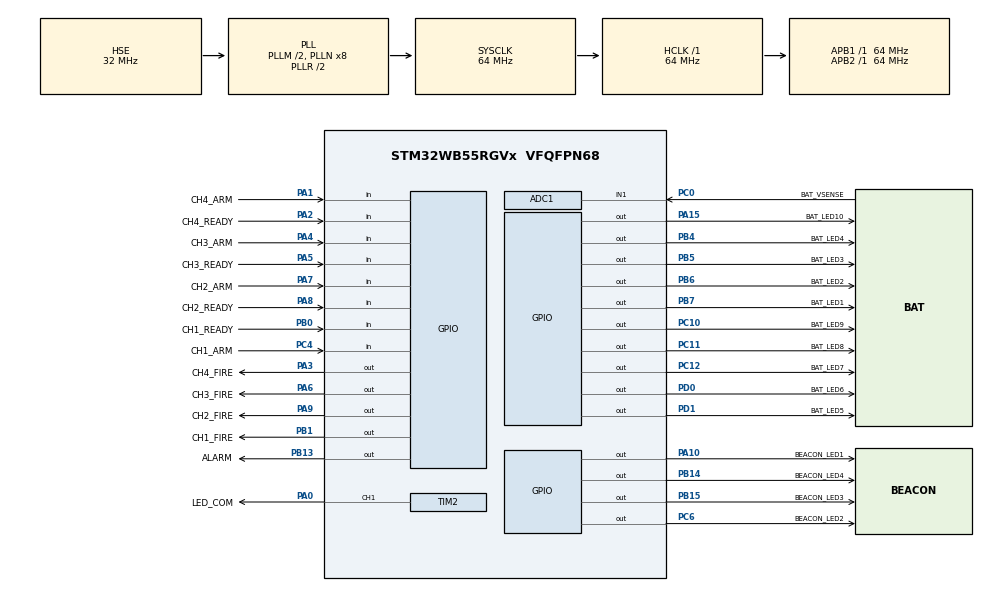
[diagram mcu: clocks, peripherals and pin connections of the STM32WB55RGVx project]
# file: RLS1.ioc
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ADC1.Channel-0\#ChannelRegularConversion=ADC_CHANNEL_1
ADC1.NbrOfConversionFlag=1
ADC1.OffsetNumber-0\#ChannelRegularConversion=ADC_OFFSET_NONE
ADC1.Rank-0\#ChannelRegularConversion=1
ADC1.SamplingTime-0\#ChannelRegularConversion=ADC_SAMPLETIME_12CYCLES_5
ADC1.master=1
Dma.Request0=TIM2_CH1
Dma.TIM2_CH1.0.Direction=DMA_MEMORY_TO_PERIPH
Dma.TIM2_CH1.0.EventEnable=DISABLE
Dma.TIM2_CH1.0.Instance=DMA1_Channel1
Dma.TIM2_CH1.0.MemDataAlignment=DMA_MDATAALIGN_BYTE
Dma.TIM2_CH1.0.MemInc=DMA_MINC_ENABLE
Dma.TIM2_CH1.0.Mode=DMA_NORMAL
Dma.TIM2_CH1.0.PeriphDataAlignment=DMA_PDATAALIGN_WORD
Dma.TIM2_CH1.0.PeriphInc=DMA_PINC_DISABLE
Dma.TIM2_CH1.0.Polarity=HAL_DMAMUX_REQ_GEN_RISING
Dma.TIM2_CH1.0.Priority=DMA_PRIORITY_LOW
Dma.TIM2_CH1.0.RequestNumber=1
Dma.TIM2_CH1.0.SignalID=NONE
Dma.TIM2_CH1.0.SyncEnable=DISABLE
Dma.TIM2_CH1.0.SyncPolarity=HAL_DMAMUX_SYNC_NO_EVENT
Dma.TIM2_CH1.0.SyncRequestNumber=1
Dma.TIM2_CH1.0.SyncSignalID=NONE
FREERTOS.Tasks01=defaultTask,24,128,StartDefaultTask,Default,NULL,Dynamic,NULL,NULL
FREERTOS.configTOTAL_HEAP_SIZE=20 * 1024
FREERTOS.configUSE_NEWLIB_REENTRANT=1
Mcu.Family=STM32WB
Mcu.Name=STM32WB55RGVx
Mcu.Package=VFQFPN68
NVIC.DMA1_Channel1_IRQn=true\:5\:0\:false\:false\:true\:true\:false\:true\:true
NVIC.HSEM_IRQn=true\:5\:0\:false\:false\:true\:true\:false\:true\:true
NVIC.IPCC_C1_RX_IRQn=true\:5\:0\:false\:false\:true\:true\:true\:true\:true
NVIC.IPCC_C1_TX_IRQn=true\:5\:0\:false\:false\:true\:true\:true\:true\:true
NVIC.PriorityGroup=NVIC_PRIORITYGROUP_4
NVIC.TIM1_TRG_COM_TIM17_IRQn=true\:15\:0\:false\:false\:true\:false\:false\:true\:true
NVIC.TIM2_IRQn=true\:5\:0\:false\:false\:true\:true\:true\:true\:true
NVIC.TimeBase=TIM1_TRG_COM_TIM17_IRQn
NVIC.TimeBaseIP=TIM17
OSC_IN.Mode=HSE-External-Oscillator
OSC_IN.Signal=RCC_OSC_IN
OSC_OUT.Mode=HSE-External-Oscillator
OSC_OUT.Signal=RCC_OSC_OUT
PA0.GPIO_Label=LED_COM
PA0.Signal=S_TIM2_CH1
PA1.GPIO_Label=CH4_ARM
PA1.Signal=GPIO_Input
PA10.GPIO_Label=BEACON_LED1
PA10.GPIO_ModeDefaultOutputPP=GPIO_MODE_OUTPUT_PP
PA10.GPIO_PuPd=GPIO_NOPULL
PA10.PinState=GPIO_PIN_RESET
PA10.Signal=GPIO_Output
PA13.Mode=Trace_Asynchronous_SW
PA13.Signal=SYS_JTMS-SWDIO
PA14.Mode=Trace_Asynchronous_SW
PA14.Signal=SYS_JTCK-SWCLK
PA15.GPIO_Label=BAT_LED10
PA15.GPIO_ModeDefaultOutputPP=GPIO_MODE_OUTPUT_OD
PA15.GPIO_PuPd=GPIO_NOPULL
PA15.PinState=GPIO_PIN_SET
PA15.Signal=GPIO_Output
PA2.GPIO_Label=CH4_READY
PA2.Signal=GPIO_Input
PA3.GPIO_Label=CH4_FIRE
PA3.Signal=GPIO_Output
PA4.GPIO_Label=CH3_ARM
PA4.Signal=GPIO_Input
PA5.GPIO_Label=CH3_READY
PA5.Signal=GPIO_Input
PA6.GPIO_Label=CH3_FIRE
PA6.Signal=GPIO_Output
PA7.GPIO_Label=CH2_ARM
PA7.Signal=GPIO_Input
PA8.GPIO_Label=CH2_READY
PA8.Signal=GPIO_Input
PA9.GPIO_Label=CH2_FIRE
PA9.Signal=GPIO_Output
PB0.GPIO_Label=CH1_READY
PB0.Signal=GPIO_Input
PB1.GPIO_Label=CH1_FIRE
PB1.Signal=GPIO_Output
PB13.GPIO_Label=ALARM
PB13.Signal=GPIO_Output
PB14.GPIO_Label=BEACON_LED4
PB14.Signal=GPIO_Output
PB15.GPIO_Label=BEACON_LED3
PB15.Signal=GPIO_Output
PB3.Mode=Trace_Asynchronous_SW
PB3.Signal=SYS_JTDO-SWO
PB4.GPIO_Label=BAT_LED4
PB4.GPIO_ModeDefaultOutputPP=GPIO_MODE_OUTPUT_OD
PB4.GPIO_PuPd=GPIO_NOPULL
PB4.PinState=GPIO_PIN_SET
PB4.Signal=GPIO_Output
PB5.GPIO_Label=BAT_LED3
PB5.GPIO_ModeDefaultOutputPP=GPIO_MODE_OUTPUT_OD
PB5.GPIO_PuPd=GPIO_NOPULL
PB5.PinState=GPIO_PIN_SET
PB5.Signal=GPIO_Output
PB6.GPIO_Label=BAT_LED2
PB6.GPIO_ModeDefaultOutputPP=GPIO_MODE_OUTPUT_OD
PB6.GPIO_PuPd=GPIO_NOPULL
PB6.PinState=GPIO_PIN_SET
PB6.Signal=GPIO_Output
PB7.GPIO_Label=BAT_LED1
PB7.GPIO_ModeDefaultOutputPP=GPIO_MODE_OUTPUT_OD
PB7.GPIO_PuPd=GPIO_NOPULL
PB7.PinState=GPIO_PIN_SET
PB7.Signal=GPIO_Output
PC0.GPIO_Label=BAT_VSENSE
PC0.Signal=ADCx_IN1
PC10.GPIO_Label=BAT_LED9
PC10.GPIO_ModeDefaultOutputPP=GPIO_MODE_OUTPUT_OD
PC10.GPIO_PuPd=GPIO_NOPULL
PC10.PinState=GPIO_PIN_SET
PC10.Signal=GPIO_Output
PC11.GPIO_Label=BAT_LED8
PC11.GPIO_ModeDefaultOutputPP=GPIO_MODE_OUTPUT_OD
PC11.GPIO_PuPd=GPIO_NOPULL
PC11.PinState=GPIO_PIN_SET
PC11.Signal=GPIO_Output
PC12.GPIO_Label=BAT_LED7
PC12.GPIO_ModeDefaultOutputPP=GPIO_MODE_OUTPUT_OD
PC12.GPIO_PuPd=GPIO_NOPULL
PC12.PinState=GPIO_PIN_SET
PC12.Signal=GPIO_Output
PC14-OSC32_IN.Mode=LSE-External-Oscillator
PC14-OSC32_IN.Signal=RCC_OSC32_IN
PC15-OSC32_OUT.Mode=LSE-External-Oscillator
PC15-OSC32_OUT.Signal=RCC_OSC32_OUT
PC4.GPIO_Label=CH1_ARM
PC4.Signal=GPIO_Input
PC6.GPIO_Label=BEACON_LED2
PC6.Signal=GPIO_Output
PD0.GPIO_Label=BAT_LED6
PD0.GPIO_ModeDefaultOutputPP=GPIO_MODE_OUTPUT_OD
PD0.GPIO_PuPd=GPIO_NOPULL
PD0.PinState=GPIO_PIN_SET
PD0.Signal=GPIO_Output
PD1.GPIO_Label=BAT_LED5
PD1.GPIO_ModeDefaultOutputPP=GPIO_MODE_OUTPUT_OD
PD1.GPIO_PuPd=GPIO_NOPULL
PD1.PinState=GPIO_PIN_SET
PD1.Signal=GPIO_Output
ProjectManager.HeapSize=0x400
ProjectManager.StackSize=0x1000
ProjectManager.TargetToolchain=STM32CubeIDE
RCC.ADCFreq_Value=64000000
RCC.AHB2CLKDivider=RCC_SYSCLK_DIV2
RCC.AHBFreq_Value=64000000
RCC.APB1Freq_Value=64000000
RCC.APB1TimFreq_Value=64000000
RCC.APB2Freq_Value=64000000
RCC.APB2TimFreq_Value=64000000
RCC.APB3Freq_Value=16000000
RCC.CortexFreq_Value=64000000
RCC.HCLKFreq_Value=64000000
RCC.HSE_VALUE=32000000
RCC.HSI48_VALUE=48000000
RCC.HSI_VALUE=16000000
RCC.PLLM=RCC_PLLM_DIV2
RCC.PLLSourceVirtual=RCC_PLLSOURCE_HSE
RCC.RFWKPClockSelection=RCC_RFWKPCLKSOURCE_LSE
RCC.RTCClockSelection=RCC_RTCCLKSOURCE_LSE
RCC.SMPSCLockSelection=RCC_SMPSCLKSOURCE_HSE
RCC.SMPSDivider=4
RCC.SYSCLKFreq_VALUE=64000000
RCC.SYSCLKSource=RCC_SYSCLKSOURCE_PLLCLK
RCC.USBFreq_Value=64000000
RCC.VCOOutputFreq_Value=128000000
RF1.Mode=RF1_Activate
RF1.Signal=RF_RF1
SH.ADCx_IN1.0=ADC1_IN1,IN1-Single-Ended
SH.S_TIM2_CH1.0=TIM2_CH1,PWM Generation1 CH1
STM32_WPAN.CFG_HW_RESET_BY_FW=1
STM32_WPAN.CFG_TX_POWER=(0x1F) /* 6dBm */
STM32_WPAN.LOCAL_NAME=RLS-1
STM32_WPAN.LOCAL_NAME_FORMATTED=,'R','L','S','-','1'
TIM2.Channel-PWM\ Generation1\ CH1=TIM_CHANNEL_1
TIM2.Period=80-1
TIM2.Prescaler=0
VP_FREERTOS_VS_CMSIS_V2.Mode=CMSIS_V2
VP_HSEM_VS_HSEM.Mode=HSEM_Activate
VP_IPCC_VS_IPCC.Mode=IPCC_Activate
VP_MEMORYMAP_VS_MEMORYMAP.Mode=CurAppReg
VP_RTC_VS_RTC_Activate.Mode=RTC_Enabled
VP_STM32_WPAN_VS_BLE_HOST.Mode=STM32_WPAN_Enabled
VP_SYS_VS_tim17.Mode=TIM17
VP_TIM2_VS_ClockSourceINT.Mode=Internal
VP_TINY_LPM_VS_TINY_LPM.Mode=TINY_LPM_Enabled
board=custom

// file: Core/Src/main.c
/* USER CODE BEGIN Header */
/**
  ******************************************************************************
  * @file           : main.c
  * @brief          : Main program body
  ******************************************************************************
  * @attention
  *
  * Copyright (c) 2024 STMicroelectronics.
  * All rights reserved.
  *
  * This software is licensed under terms that can be found in the LICENSE file
  * in the root directory of this software component.
  * If no LICENSE file comes with this software, it is provided AS-IS.
  *
  ******************************************************************************
  */
/* USER CODE END Header */
#include "main.h"
#include "cmsis_os.h"

/* USER CODE BEGIN Includes */
#include "rls.h"
/* USER CODE END Includes */

ADC_HandleTypeDef hadc1;

IPCC_HandleTypeDef hipcc;

RTC_HandleTypeDef hrtc;

TIM_HandleTypeDef htim2;
DMA_HandleTypeDef hdma_tim2_ch1;

/* Definitions for defaultTask */
osThreadId_t defaultTaskHandle;
const osThreadAttr_t defaultTask_attributes = {
  .name = "defaultTask",
  .priority = (osPriority_t) osPriorityNormal,
  .stack_size = 128 * 4
};

void SystemClock_Config(void);
void PeriphCommonClock_Config(void);
static void MX_GPIO_Init(void);
static void MX_DMA_Init(void);
static void MX_RTC_Init(void);
static void MX_TIM2_Init(void);
static void MX_IPCC_Init(void);
static void MX_ADC1_Init(void);
static void MX_RF_Init(void);
void StartDefaultTask(void *argument);

int main(void)
{

  /* MCU Configuration--------------------------------------------------------*/

  /* Reset of all peripherals, Initializes the Flash interface and the Systick. */
  HAL_Init();
  /* Config code for STM32_WPAN (HSE Tuning must be done before system clock configuration) */
  MX_APPE_Config();

  /* Configure the system clock */
  SystemClock_Config();

/* Configure the peripherals common clocks */
  PeriphCommonClock_Config();

  /* IPCC initialisation */
  MX_IPCC_Init();

  /* Initialize all configured peripherals */
  MX_GPIO_Init();
  MX_DMA_Init();
  MX_RTC_Init();
  MX_TIM2_Init();
  MX_ADC1_Init();
  MX_RF_Init();

  /* Init scheduler */
  osKernelInitialize();

  /* Create the thread(s) */
  /* creation of defaultTask */
  defaultTaskHandle = osThreadNew(StartDefaultTask, NULL, &defaultTask_attributes);

  /* USER CODE BEGIN RTOS_EVENTS */
  /* add events, ... */
  RLS_Init();
  /* USER CODE END RTOS_EVENTS */

  /* Init code for STM32_WPAN */
  MX_APPE_Init();

  /* Start scheduler */
  osKernelStart();

  /* We should never get here as control is now taken by the scheduler */

  /* Infinite loop */
  while (1)
  {

  }
}

void SystemClock_Config(void)
{
  RCC_OscInitTypeDef RCC_OscInitStruct = {0};
  RCC_ClkInitTypeDef RCC_ClkInitStruct = {0};

  /** Configure LSE Drive Capability
  */
  HAL_PWR_EnableBkUpAccess();
  __HAL_RCC_LSEDRIVE_CONFIG(RCC_LSEDRIVE_MEDIUMHIGH);

  /** Configure the main internal regulator output voltage
  */
  __HAL_PWR_VOLTAGESCALING_CONFIG(PWR_REGULATOR_VOLTAGE_SCALE1);

  /** Initializes the RCC Oscillators according to the specified parameters
  * in the RCC_OscInitTypeDef structure.
  */
  RCC_OscInitStruct.OscillatorType = RCC_OSCILLATORTYPE_HSI|RCC_OSCILLATORTYPE_HSE
                              |RCC_OSCILLATORTYPE_LSE;
  RCC_OscInitStruct.HSEState = RCC_HSE_ON;
  RCC_OscInitStruct.LSEState = RCC_LSE_ON;
  RCC_OscInitStruct.HSIState = RCC_HSI_ON;
  RCC_OscInitStruct.HSICalibrationValue = RCC_HSICALIBRATION_DEFAULT;
  RCC_OscInitStruct.PLL.PLLState = RCC_PLL_ON;
  RCC_OscInitStruct.PLL.PLLSource = RCC_PLLSOURCE_HSE;
  RCC_OscInitStruct.PLL.PLLM = RCC_PLLM_DIV2;
  RCC_OscInitStruct.PLL.PLLN = 8;
  RCC_OscInitStruct.PLL.PLLP = RCC_PLLP_DIV2;
  RCC_OscInitStruct.PLL.PLLR = RCC_PLLR_DIV2;
  RCC_OscInitStruct.PLL.PLLQ = RCC_PLLQ_DIV2;
  if (HAL_RCC_OscConfig(&RCC_OscInitStruct) != HAL_OK)
  {
    Error_Handler();
  }

  /** Configure the SYSCLKSource, HCLK, PCLK1 and PCLK2 clocks dividers
  */
  RCC_ClkInitStruct.ClockType = RCC_CLOCKTYPE_HCLK4|RCC_CLOCKTYPE_HCLK2
                              |RCC_CLOCKTYPE_HCLK|RCC_CLOCKTYPE_SYSCLK
                              |RCC_CLOCKTYPE_PCLK1|RCC_CLOCKTYPE_PCLK2;
  RCC_ClkInitStruct.SYSCLKSource = RCC_SYSCLKSOURCE_PLLCLK;
  RCC_ClkInitStruct.AHBCLKDivider = RCC_SYSCLK_DIV1;
  RCC_ClkInitStruct.APB1CLKDivider = RCC_HCLK_DIV1;
  RCC_ClkInitStruct.APB2CLKDivider = RCC_HCLK_DIV1;
  RCC_ClkInitStruct.AHBCLK2Divider = RCC_SYSCLK_DIV2;
  RCC_ClkInitStruct.AHBCLK4Divider = RCC_SYSCLK_DIV1;

  if (HAL_RCC_ClockConfig(&RCC_ClkInitStruct, FLASH_LATENCY_3) != HAL_OK)
  {
    Error_Handler();
  }
}

void PeriphCommonClock_Config(void)
{
  RCC_PeriphCLKInitTypeDef PeriphClkInitStruct = {0};

  /** Initializes the peripherals clock
  */
  PeriphClkInitStruct.PeriphClockSelection = RCC_PERIPHCLK_SMPS|RCC_PERIPHCLK_RFWAKEUP;
  PeriphClkInitStruct.RFWakeUpClockSelection = RCC_RFWKPCLKSOURCE_LSE;
  PeriphClkInitStruct.SmpsClockSelection = RCC_SMPSCLKSOURCE_HSE;
  PeriphClkInitStruct.SmpsDivSelection = RCC_SMPSCLKDIV_RANGE1;

  if (HAL_RCCEx_PeriphCLKConfig(&PeriphClkInitStruct) != HAL_OK)
  {
    Error_Handler();
  }
}

static void MX_ADC1_Init(void)
{

  ADC_ChannelConfTypeDef sConfig = {0};

  /** Common config
  */
  hadc1.Instance = ADC1;
  hadc1.Init.ClockPrescaler = ADC_CLOCK_ASYNC_DIV8;
  hadc1.Init.Resolution = ADC_RESOLUTION_12B;
  hadc1.Init.DataAlign = ADC_DATAALIGN_RIGHT;
  hadc1.Init.ScanConvMode = ADC_SCAN_ENABLE;
  hadc1.Init.EOCSelection = ADC_EOC_SINGLE_CONV;
  hadc1.Init.LowPowerAutoWait = DISABLE;
  hadc1.Init.ContinuousConvMode = DISABLE;
  hadc1.Init.NbrOfConversion = 2;
  hadc1.Init.DiscontinuousConvMode = DISABLE;
  hadc1.Init.ExternalTrigConv = ADC_SOFTWARE_START;
  hadc1.Init.ExternalTrigConvEdge = ADC_EXTERNALTRIGCONVEDGE_NONE;
  hadc1.Init.DMAContinuousRequests = DISABLE;
  hadc1.Init.Overrun = ADC_OVR_DATA_PRESERVED;
  hadc1.Init.OversamplingMode = DISABLE;
  if (HAL_ADC_Init(&hadc1) != HAL_OK)
  {
    Error_Handler();
  }

  sConfig.Channel = ADC_CHANNEL_VREFINT;
  sConfig.Rank = ADC_REGULAR_RANK_1;
  sConfig.SamplingTime = ADC_SAMPLETIME_247CYCLES_5;
  sConfig.SingleDiff = ADC_SINGLE_ENDED;
  sConfig.OffsetNumber = ADC_OFFSET_NONE;
  sConfig.Offset = 0;
  if (HAL_ADC_ConfigChannel(&hadc1, &sConfig) != HAL_OK)
  {
    Error_Handler();
  }

  /** Configure Regular Channel
  */
  sConfig.Channel = ADC_CHANNEL_1;
  sConfig.Rank = ADC_REGULAR_RANK_2;
  sConfig.SamplingTime = ADC_SAMPLETIME_247CYCLES_5;
  sConfig.SingleDiff = ADC_SINGLE_ENDED;
  sConfig.OffsetNumber = ADC_OFFSET_NONE;
  sConfig.Offset = 0;
  if (HAL_ADC_ConfigChannel(&hadc1, &sConfig) != HAL_OK)
  {
    Error_Handler();
  }

}

static void MX_IPCC_Init(void)
{

  hipcc.Instance = IPCC;
  if (HAL_IPCC_Init(&hipcc) != HAL_OK)
  {
    Error_Handler();
  }

}

static void MX_RF_Init(void)
{

}

static void MX_RTC_Init(void)
{

  /** Initialize RTC Only
  */
  hrtc.Instance = RTC;
  hrtc.Init.HourFormat = RTC_HOURFORMAT_24;
  hrtc.Init.AsynchPrediv = CFG_RTC_ASYNCH_PRESCALER;
  hrtc.Init.SynchPrediv = CFG_RTC_SYNCH_PRESCALER;
  hrtc.Init.OutPut = RTC_OUTPUT_DISABLE;
  hrtc.Init.OutPutPolarity = RTC_OUTPUT_POLARITY_HIGH;
  hrtc.Init.OutPutType = RTC_OUTPUT_TYPE_OPENDRAIN;
  hrtc.Init.OutPutRemap = RTC_OUTPUT_REMAP_NONE;
  if (HAL_RTC_Init(&hrtc) != HAL_OK)
  {
    Error_Handler();
  }
  /* USER CODE BEGIN RTC_Init 2 */
  /** Enable the WakeUp
  */
  if (HAL_RTCEx_SetWakeUpTimer_IT(&hrtc, 0, RTC_WAKEUPCLOCK_RTCCLK_DIV16) != HAL_OK)
  {
    Error_Handler();
  }
  /* USER CODE END RTC_Init 2 */

}

static void MX_TIM2_Init(void)
{

  TIM_ClockConfigTypeDef sClockSourceConfig = {0};
  TIM_MasterConfigTypeDef sMasterConfig = {0};
  TIM_OC_InitTypeDef sConfigOC = {0};

  htim2.Instance = TIM2;
  htim2.Init.Prescaler = 0;
  htim2.Init.CounterMode = TIM_COUNTERMODE_UP;
  htim2.Init.Period = 80-1;
  htim2.Init.ClockDivision = TIM_CLOCKDIVISION_DIV1;
  htim2.Init.AutoReloadPreload = TIM_AUTORELOAD_PRELOAD_DISABLE;
  if (HAL_TIM_Base_Init(&htim2) != HAL_OK)
  {
    Error_Handler();
  }
  sClockSourceConfig.ClockSource = TIM_CLOCKSOURCE_INTERNAL;
  if (HAL_TIM_ConfigClockSource(&htim2, &sClockSourceConfig) != HAL_OK)
  {
    Error_Handler();
  }
  if (HAL_TIM_PWM_Init(&htim2) != HAL_OK)
  {
    Error_Handler();
  }
  sMasterConfig.MasterOutputTrigger = TIM_TRGO_RESET;
  sMasterConfig.MasterSlaveMode = TIM_MASTERSLAVEMODE_DISABLE;
  if (HAL_TIMEx_MasterConfigSynchronization(&htim2, &sMasterConfig) != HAL_OK)
  {
    Error_Handler();
  }
  sConfigOC.OCMode = TIM_OCMODE_PWM1;
  sConfigOC.Pulse = 0;
  sConfigOC.OCPolarity = TIM_OCPOLARITY_HIGH;
  sConfigOC.OCFastMode = TIM_OCFAST_DISABLE;
  if (HAL_TIM_PWM_ConfigChannel(&htim2, &sConfigOC, TIM_CHANNEL_1) != HAL_OK)
  {
    Error_Handler();
  }
  HAL_TIM_MspPostInit(&htim2);

}

static void MX_DMA_Init(void)
{

  /* DMA controller clock enable */
  __HAL_RCC_DMAMUX1_CLK_ENABLE();
  __HAL_RCC_DMA1_CLK_ENABLE();

  /* DMA interrupt init */
  /* DMA1_Channel1_IRQn interrupt configuration */
  HAL_NVIC_SetPriority(DMA1_Channel1_IRQn, 5, 0);
  HAL_NVIC_EnableIRQ(DMA1_Channel1_IRQn);

}

static void MX_GPIO_Init(void)
{
  GPIO_InitTypeDef GPIO_InitStruct = {0};

  /* GPIO Ports Clock Enable */
  __HAL_RCC_GPIOC_CLK_ENABLE();
  __HAL_RCC_GPIOA_CLK_ENABLE();
  __HAL_RCC_GPIOB_CLK_ENABLE();
  __HAL_RCC_GPIOD_CLK_ENABLE();

  /*Configure GPIO pin Output Level */
  HAL_GPIO_WritePin(GPIOA, CH4_FIRE_Pin|CH3_FIRE_Pin|CH2_FIRE_Pin|BEACON_LED1_Pin, GPIO_PIN_RESET);

  /*Configure GPIO pin Output Level */
  HAL_GPIO_WritePin(GPIOB, CH1_FIRE_Pin|ALARM_Pin|BEACON_LED4_Pin|BEACON_LED3_Pin, GPIO_PIN_RESET);

  /*Configure GPIO pin Output Level */
  HAL_GPIO_WritePin(BEACON_LED2_GPIO_Port, BEACON_LED2_Pin, GPIO_PIN_RESET);

  /*Configure GPIO pin Output Level */
  HAL_GPIO_WritePin(BAT_LED10_GPIO_Port, BAT_LED10_Pin, GPIO_PIN_SET);

  /*Configure GPIO pin Output Level */
  HAL_GPIO_WritePin(GPIOC, BAT_LED9_Pin|BAT_LED8_Pin|BAT_LED7_Pin, GPIO_PIN_SET);

  /*Configure GPIO pin Output Level */
  HAL_GPIO_WritePin(GPIOD, BAT_LED6_Pin|BAT_LED5_Pin, GPIO_PIN_SET);

  /*Configure GPIO pin Output Level */
  HAL_GPIO_WritePin(GPIOB, BAT_LED4_Pin|BAT_LED3_Pin|BAT_LED2_Pin|BAT_LED1_Pin, GPIO_PIN_SET);

  /*Configure GPIO pins : CH4_ARM_Pin CH4_READY_Pin CH3_ARM_Pin CH3_READY_Pin
                           CH2_ARM_Pin CH2_READY_Pin */
  GPIO_InitStruct.Pin = CH4_ARM_Pin|CH4_READY_Pin|CH3_ARM_Pin|CH3_READY_Pin
                          |CH2_ARM_Pin|CH2_READY_Pin;
  GPIO_InitStruct.Mode = GPIO_MODE_INPUT;
  GPIO_InitStruct.Pull = GPIO_NOPULL;
  HAL_GPIO_Init(GPIOA, &GPIO_InitStruct);

  /*Configure GPIO pins : CH4_FIRE_Pin CH3_FIRE_Pin CH2_FIRE_Pin BEACON_LED1_Pin */
  GPIO_InitStruct.Pin = CH4_FIRE_Pin|CH3_FIRE_Pin|CH2_FIRE_Pin|BEACON_LED1_Pin;
  GPIO_InitStruct.Mode = GPIO_MODE_OUTPUT_PP;
  GPIO_InitStruct.Pull = GPIO_NOPULL;
  GPIO_InitStruct.Speed = GPIO_SPEED_FREQ_LOW;
  HAL_GPIO_Init(GPIOA, &GPIO_InitStruct);

  /*Configure GPIO pin : CH1_ARM_Pin */
  GPIO_InitStruct.Pin = CH1_ARM_Pin;
  GPIO_InitStruct.Mode = GPIO_MODE_INPUT;
  GPIO_InitStruct.Pull = GPIO_NOPULL;
  HAL_GPIO_Init(CH1_ARM_GPIO_Port, &GPIO_InitStruct);

  /*Configure GPIO pin : CH1_READY_Pin */
  GPIO_InitStruct.Pin = CH1_READY_Pin;
  GPIO_InitStruct.Mode = GPIO_MODE_INPUT;
  GPIO_InitStruct.Pull = GPIO_NOPULL;
  HAL_GPIO_Init(CH1_READY_GPIO_Port, &GPIO_InitStruct);

  /*Configure GPIO pins : CH1_FIRE_Pin ALARM_Pin BEACON_LED4_Pin BEACON_LED3_Pin */
  GPIO_InitStruct.Pin = CH1_FIRE_Pin|ALARM_Pin|BEACON_LED4_Pin|BEACON_LED3_Pin;
  GPIO_InitStruct.Mode = GPIO_MODE_OUTPUT_PP;
  GPIO_InitStruct.Pull = GPIO_NOPULL;
  GPIO_InitStruct.Speed = GPIO_SPEED_FREQ_LOW;
  HAL_GPIO_Init(GPIOB, &GPIO_InitStruct);

  /*Configure GPIO pin : BEACON_LED2_Pin */
  GPIO_InitStruct.Pin = BEACON_LED2_Pin;
  GPIO_InitStruct.Mode = GPIO_MODE_OUTPUT_PP;
  GPIO_InitStruct.Pull = GPIO_NOPULL;
  GPIO_InitStruct.Speed = GPIO_SPEED_FREQ_LOW;
  HAL_GPIO_Init(BEACON_LED2_GPIO_Port, &GPIO_InitStruct);

  /*Configure GPIO pin : BAT_LED10_Pin */
  GPIO_InitStruct.Pin = BAT_LED10_Pin;
  GPIO_InitStruct.Mode = GPIO_MODE_OUTPUT_OD;
  GPIO_InitStruct.Pull = GPIO_NOPULL;
  GPIO_InitStruct.Speed = GPIO_SPEED_FREQ_LOW;
  HAL_GPIO_Init(BAT_LED10_GPIO_Port, &GPIO_InitStruct);

  /*Configure GPIO pins : BAT_LED9_Pin BAT_LED8_Pin BAT_LED7_Pin */
  GPIO_InitStruct.Pin = BAT_LED9_Pin|BAT_LED8_Pin|BAT_LED7_Pin;
  GPIO_InitStruct.Mode = GPIO_MODE_OUTPUT_OD;
  GPIO_InitStruct.Pull = GPIO_NOPULL;
  GPIO_InitStruct.Speed = GPIO_SPEED_FREQ_LOW;
  HAL_GPIO_Init(GPIOC, &GPIO_InitStruct);

  /*Configure GPIO pins : BAT_LED6_Pin BAT_LED5_Pin */
  GPIO_InitStruct.Pin = BAT_LED6_Pin|BAT_LED5_Pin;
  GPIO_InitStruct.Mode = GPIO_MODE_OUTPUT_OD;
  GPIO_InitStruct.Pull = GPIO_NOPULL;
  GPIO_InitStruct.Speed = GPIO_SPEED_FREQ_LOW;
  HAL_GPIO_Init(GPIOD, &GPIO_InitStruct);

  /*Configure GPIO pins : BAT_LED4_Pin BAT_LED3_Pin BAT_LED2_Pin BAT_LED1_Pin */
  GPIO_InitStruct.Pin = BAT_LED4_Pin|BAT_LED3_Pin|BAT_LED2_Pin|BAT_LED1_Pin;
  GPIO_InitStruct.Mode = GPIO_MODE_OUTPUT_OD;
  GPIO_InitStruct.Pull = GPIO_NOPULL;
  GPIO_InitStruct.Speed = GPIO_SPEED_FREQ_LOW;
  HAL_GPIO_Init(GPIOB, &GPIO_InitStruct);

}

void StartDefaultTask(void *argument)
{
  /* USER CODE BEGIN 5 */
  /* Infinite loop */
  for(;;)
  {
	  osThreadFlagsWait(1,osFlagsWaitAll,osWaitForever);
  }
  /* USER CODE END 5 */
}

void HAL_TIM_PeriodElapsedCallback(TIM_HandleTypeDef *htim)
{
  if (htim->Instance == TIM17) {
    HAL_IncTick();
  }
}

void Error_Handler(void)
{
  __disable_irq();
  while (1)
  {
  }
}
